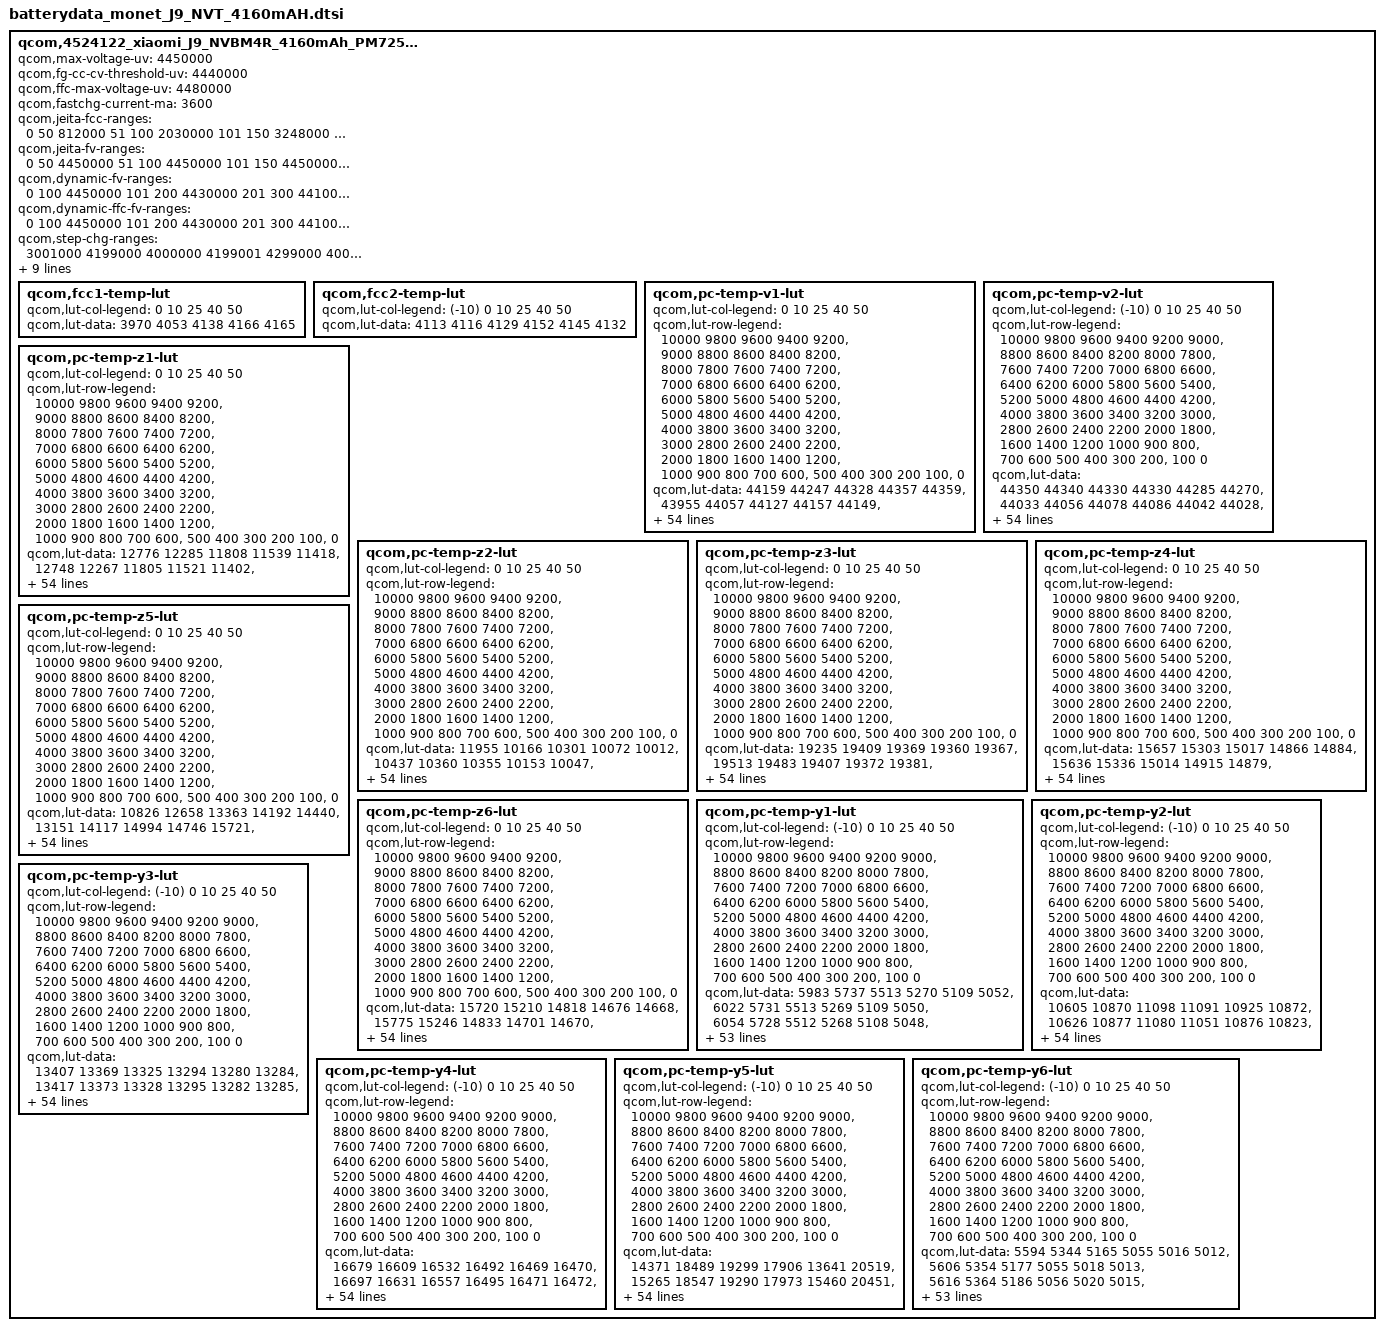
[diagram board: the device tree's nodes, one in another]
qcom,4524122_xiaomi_J9_NVBM4R_4160mAh_PM7250B {
    /* 4524122_xiaomi_J9_NVBM4R_4160mAh_PM7250B_averaged_MasterSlave_Mar27th2020 */
    qcom,max-voltage-uv = <4450000>;
    qcom,fg-cc-cv-threshold-uv = <4440000>;
    qcom,ffc-max-voltage-uv = <4480000>;
    qcom,fastchg-current-ma = <3600>;
    qcom,jeita-fcc-ranges = <0  50  812000
			     51  100  2030000
			     101 150  3248000
			     151 450  3600000
			     451 580  2030000>;
    qcom,jeita-fv-ranges = <0   50  4450000
			    51  100  4450000
			    101 150  4450000
			    151 450  4480000
			    451 580  4100000>;
    qcom,dynamic-fv-ranges = <0    100  4450000
			    101  200  4430000
			    201  300  4410000
			    301  400  4390000
			    401  500  4370000>;
    qcom,dynamic-ffc-fv-ranges = <0    100  4450000
			    101  200  4430000
			    201  300  4410000
			    301  400  4390000
			    401  500  4370000>;
    qcom,step-chg-ranges = <3001000  4199000  4000000
			    4199001  4299000  4000000
			    4299001  4399000  4000000
                            4399001  4450000  4000000
                            4450001  4480000  3248000>;
    qcom,batt-id-kohm = <68>;
    qcom,fg-cc-cv-threshold-mv = <4440>;
    qcom,nom-batt-capacity-mah = <4160>;
    qcom,battery-beta = <4250>;
    qcom,battery-therm-kohm = <100>;
    qcom,cutoff-current-ua = <850000>;
    qcom,battery-type = "J9_NVT_4160mAH";
    qcom,qg-batt-profile-ver = <100>;
    mi,qc3p5-ffc-battery;

	qcom,fcc1-temp-lut {
		qcom,lut-col-legend = <0 10 25 40 50>;
		qcom,lut-data = <3970 4053 4138 4166 4165>;
	};

	qcom,fcc2-temp-lut {
		qcom,lut-col-legend = <(-10) 0 10 25 40 50>;
		qcom,lut-data = <4113 4116 4129 4152 4145 4132>;
	};

	qcom,pc-temp-v1-lut {
		qcom,lut-col-legend = <0 10 25 40 50>;
		qcom,lut-row-legend = <10000 9800 9600 9400 9200>,
			<9000 8800 8600 8400 8200>,
			<8000 7800 7600 7400 7200>,
			<7000 6800 6600 6400 6200>,
			<6000 5800 5600 5400 5200>,
			<5000 4800 4600 4400 4200>,
			<4000 3800 3600 3400 3200>,
			<3000 2800 2600 2400 2200>,
			<2000 1800 1600 1400 1200>,
			<1000 900 800 700 600>,
			<500 400 300 200 100>,
			<0>;
		qcom,lut-data = <44159 44247 44328 44357 44359>,
			<43955 44057 44127 44157 44149>,
			<43742 43859 43926 43951 43947>,
			<43523 43653 43724 43748 43746>,
			<43298 43439 43522 43546 43545>,
			<43069 43215 43309 43338 43338>,
			<42838 42984 43081 43114 43117>,
			<42602 42749 42845 42880 42888>,
			<42369 42511 42608 42644 42656>,
			<42139 42274 42366 42403 42416>,
			<41912 42040 42127 42164 42177>,
			<41698 41809 41891 41928 41941>,
			<41500 41584 41660 41697 41708>,
			<41307 41363 41432 41468 41478>,
			<41103 41149 41209 41243 41252>,
			<40892 40945 40993 41024 41033>,
			<40684 40749 40785 40813 40820>,
			<40481 40557 40585 40609 40615>,
			<40283 40372 40397 40417 40422>,
			<40097 40182 40221 40243 40247>,
			<39929 39961 40026 40057 40060>,
			<39754 39717 39780 39815 39825>,
			<39527 39499 39528 39549 39568>,
			<39265 39308 39327 39337 39356>,
			<39087 39140 39155 39163 39179>,
			<38992 39008 39007 39014 39027>,
			<38918 38901 38880 38886 38898>,
			<38837 38801 38768 38773 38784>,
			<38752 38704 38663 38668 38677>,
			<38671 38614 38566 38569 38575>,
			<38599 38534 38478 38478 38482>,
			<38530 38460 38398 38395 38396>,
			<38471 38395 38325 38317 38317>,
			<38417 38337 38259 38244 38241>,
			<38369 38285 38199 38176 38168>,
			<38327 38236 38143 38108 38094>,
			<38289 38194 38093 38042 38016>,
			<38241 38146 38042 37974 37933>,
			<38160 38071 37969 37888 37837>,
			<38053 37966 37868 37780 37722>,
			<37932 37849 37752 37659 37597>,
			<37787 37713 37622 37527 37465>,
			<37635 37560 37475 37383 37321>,
			<37476 37379 37303 37213 37148>,
			<37334 37226 37163 37091 37028>,
			<37232 37137 37083 37025 36965>,
			<37193 37107 37057 37000 36942>,
			<37163 37088 37036 36985 36923>,
			<37126 37057 37008 36946 36885>,
			<37033 36966 36872 36768 36720>,
			<36715 36631 36487 36386 36352>,
			<36225 36147 35989 35888 35871>,
			<35600 35520 35339 35239 35246>,
			<34746 34657 34443 34341 34391>,
			<33379 33271 32970 32878 33033>,
			<30000 30000 30000 30000 30000>;
	};

	qcom,pc-temp-v2-lut {
		qcom,lut-col-legend = <(-10) 0 10 25 40 50>;
		qcom,lut-row-legend = <10000 9800 9600 9400 9200 9000>,
			<8800 8600 8400 8200 8000 7800>,
			<7600 7400 7200 7000 6800 6600>,
			<6400 6200 6000 5800 5600 5400>,
			<5200 5000 4800 4600 4400 4200>,
			<4000 3800 3600 3400 3200 3000>,
			<2800 2600 2400 2200 2000 1800>,
			<1600 1400 1200 1000 900 800>,
			<700 600 500 400 300 200>,
			<100 0>;
		qcom,lut-data = <44350 44340 44330 44330 44285 44270>,
			<44033 44056 44078 44086 44042 44028>,
			<43743 43792 43840 43853 43809 43797>,
			<43484 43549 43617 43633 43590 43577>,
			<43258 43329 43410 43426 43385 43370>,
			<43034 43109 43200 43214 43175 43160>,
			<42800 42878 42971 42985 42948 42935>,
			<42562 42641 42732 42748 42712 42704>,
			<42323 42402 42493 42510 42475 42470>,
			<42079 42156 42250 42268 42233 42231>,
			<41837 41914 42010 42028 41993 41993>,
			<41593 41679 41773 41789 41757 41758>,
			<41353 41450 41540 41554 41526 41526>,
			<41150 41229 41310 41324 41298 41299>,
			<40994 41016 41085 41101 41076 41076>,
			<40821 40812 40867 40884 40860 40859>,
			<40548 40627 40663 40674 40650 40650>,
			<40200 40450 40466 40469 40447 40446>,
			<39912 40236 40264 40273 40255 40254>,
			<39684 39958 40056 40090 40079 40078>,
			<39474 39672 39838 39892 39889 39891>,
			<39261 39421 39587 39639 39643 39653>,
			<39053 39185 39318 39367 39375 39387>,
			<38863 38981 39098 39148 39159 39170>,
			<38683 38806 38919 38965 38981 38996>,
			<38525 38648 38763 38807 38827 38843>,
			<38401 38500 38626 38673 38694 38707>,
			<38298 38361 38504 38555 38577 38585>,
			<38213 38242 38391 38446 38469 38475>,
			<38143 38135 38285 38347 38368 38375>,
			<38081 38048 38188 38254 38276 38283>,
			<38020 37985 38097 38166 38193 38200>,
			<37962 37937 38013 38084 38117 38123>,
			<37902 37894 37940 38006 38038 38041>,
			<37844 37857 37878 37936 37957 37953>,
			<37784 37820 37820 37862 37870 37856>,
			<37717 37777 37765 37773 37767 37743>,
			<37643 37728 37712 37674 37653 37618>,
			<37560 37664 37646 37579 37548 37506>,
			<37466 37572 37556 37488 37454 37415>,
			<37362 37455 37449 37389 37354 37321>,
			<37246 37317 37325 37272 37234 37201>,
			<37116 37150 37181 37145 37103 37064>,
			<37005 36991 37032 37011 36966 36929>,
			<36909 36854 36906 36915 36876 36830>,
			<36829 36770 36837 36868 36841 36790>,
			<36787 36742 36809 36852 36827 36778>,
			<36739 36697 36775 36830 36805 36756>,
			<36668 36632 36712 36777 36744 36697>,
			<36506 36481 36548 36567 36504 36480>,
			<36191 36167 36164 36138 36066 36057>,
			<35712 35671 35603 35566 35497 35511>,
			<35026 35008 34862 34812 34745 34796>,
			<34045 34080 33824 33752 33703 33819>,
			<32404 32502 32079 32096 32060 32319>,
			<27319 28586 28048 26381 26476 28110>;
	};

	qcom,pc-temp-z1-lut {
		qcom,lut-col-legend = <0 10 25 40 50>;
		qcom,lut-row-legend = <10000 9800 9600 9400 9200>,
			<9000 8800 8600 8400 8200>,
			<8000 7800 7600 7400 7200>,
			<7000 6800 6600 6400 6200>,
			<6000 5800 5600 5400 5200>,
			<5000 4800 4600 4400 4200>,
			<4000 3800 3600 3400 3200>,
			<3000 2800 2600 2400 2200>,
			<2000 1800 1600 1400 1200>,
			<1000 900 800 700 600>,
			<500 400 300 200 100>,
			<0>;
		qcom,lut-data = <12776 12285 11808 11539 11418>,
			<12748 12267 11805 11521 11402>,
			<12735 12255 11799 11508 11395>,
			<12727 12247 11791 11497 11388>,
			<12720 12238 11779 11488 11381>,
			<12711 12226 11767 11480 11376>,
			<12696 12212 11753 11473 11372>,
			<12663 12198 11742 11468 11369>,
			<12636 12182 11736 11464 11367>,
			<12627 12172 11733 11462 11366>,
			<12621 12163 11729 11460 11365>,
			<12614 12153 11725 11457 11363>,
			<12598 12150 11721 11454 11362>,
			<12581 12147 11717 11453 11361>,
			<12574 12144 11714 11452 11360>,
			<12570 12141 11713 11451 11360>,
			<12566 12138 11714 11450 11360>,
			<12549 12137 11716 11450 11361>,
			<12529 12134 11715 11450 11361>,
			<12523 12131 11712 11451 11363>,
			<12523 12130 11710 11453 11364>,
			<12523 12129 11711 11452 11364>,
			<12528 12129 11713 11450 11363>,
			<12542 12128 11715 11450 11363>,
			<12548 12126 11719 11452 11365>,
			<12542 12129 11723 11455 11367>,
			<12533 12140 11725 11458 11370>,
			<12535 12147 11726 11462 11373>,
			<12544 12148 11730 11466 11376>,
			<12551 12147 11738 11469 11379>,
			<12548 12146 11744 11472 11382>,
			<12541 12145 11748 11476 11385>,
			<12538 12145 11751 11480 11388>,
			<12540 12150 11754 11485 11392>,
			<12545 12159 11758 11491 11397>,
			<12554 12166 11762 11497 11402>,
			<12571 12177 11769 11502 11406>,
			<12586 12187 11776 11508 11410>,
			<12592 12193 11782 11513 11415>,
			<12599 12198 11786 11516 11422>,
			<12612 12200 11790 11520 11427>,
			<12639 12204 11796 11524 11429>,
			<12655 12210 11804 11528 11430>,
			<12662 12229 11813 11531 11430>,
			<12661 12227 11823 11535 11433>,
			<12669 12237 11818 11538 11434>,
			<12663 12264 11823 11538 11436>,
			<12661 12407 11821 11542 11437>,
			<12658 12238 11822 11544 11440>,
			<12665 12262 11839 11549 11442>,
			<12696 12256 11838 11553 11448>,
			<12704 12266 11841 11561 11454>,
			<12697 12292 11856 11566 11463>,
			<12720 12299 11873 11581 11474>,
			<12720 12299 11873 11581 11474>,
			<12720 12299 11873 11581 11474>;
	};

	qcom,pc-temp-z2-lut {
		qcom,lut-col-legend = <0 10 25 40 50>;
		qcom,lut-row-legend = <10000 9800 9600 9400 9200>,
			<9000 8800 8600 8400 8200>,
			<8000 7800 7600 7400 7200>,
			<7000 6800 6600 6400 6200>,
			<6000 5800 5600 5400 5200>,
			<5000 4800 4600 4400 4200>,
			<4000 3800 3600 3400 3200>,
			<3000 2800 2600 2400 2200>,
			<2000 1800 1600 1400 1200>,
			<1000 900 800 700 600>,
			<500 400 300 200 100>,
			<0>;
		qcom,lut-data = <11955 10166 10301 10072 10012>,
			<10437 10360 10355 10153 10047>,
			<10314 10378 10382 10150 10027>,
			<10266 10374 10375 10146 10011>,
			<10252 10366 10344 10146 10009>,
			<10241 10348 10314 10143 10012>,
			<10227 10323 10285 10133 9999>,
			<10207 10302 10256 10117 9965>,
			<10192 10282 10233 10100 9946>,
			<10184 10266 10213 10078 9946>,
			<10179 10253 10205 10058 9954>,
			<10189 10243 10207 10034 9947>,
			<10385 10244 10212 10006 9925>,
			<10603 10265 10217 9999 9917>,
			<10571 10287 10228 9987 9922>,
			<10354 10296 10238 9979 9929>,
			<10222 10302 10246 9987 9942>,
			<10228 10308 10252 9999 9959>,
			<10240 10314 10256 10009 9968>,
			<10249 10319 10259 10015 9975>,
			<10257 10326 10265 10024 9986>,
			<10262 10332 10310 10126 10053>,
			<10260 10334 10360 10306 10169>,
			<10254 10319 10361 10375 10246>,
			<10248 10301 10340 10399 10305>,
			<10237 10306 10329 10408 10333>,
			<10227 10336 10330 10336 10248>,
			<10226 10353 10330 10193 10075>,
			<10230 10346 10320 10114 9969>,
			<10235 10336 10277 10072 9897>,
			<10244 10334 10251 10039 9863>,
			<10257 10336 10246 10005 9867>,
			<10269 10339 10243 9977 9878>,
			<10279 10346 10251 9977 9893>,
			<10289 10356 10293 10017 9928>,
			<10296 10364 10331 10062 9972>,
			<10303 10369 10351 10097 10024>,
			<10312 10376 10369 10134 10081>,
			<10333 10391 10396 10173 10123>,
			<10356 10412 10435 10226 10158>,
			<10362 10421 10455 10271 10175>,
			<10360 10423 10456 10305 10163>,
			<10336 10425 10457 10324 10145>,
			<10208 10440 10454 10308 10146>,
			<10607 10573 10475 10239 10128>,
			<10770 10624 10465 10177 10081>,
			<10868 10605 10439 10188 10089>,
			<11496 10612 10455 10214 10109>,
			<12103 10624 10450 10272 10182>,
			<11607 10753 10526 10229 10165>,
			<10857 10809 10419 10062 9989>,
			<10957 10849 10365 10021 9931>,
			<10457 10891 10314 9977 9891>,
			<10210 10754 10267 9925 9829>,
			<10210 10754 10267 9925 9829>,
			<10210 10754 10267 9925 9829>;
	};

	qcom,pc-temp-z3-lut {
		qcom,lut-col-legend = <0 10 25 40 50>;
		qcom,lut-row-legend = <10000 9800 9600 9400 9200>,
			<9000 8800 8600 8400 8200>,
			<8000 7800 7600 7400 7200>,
			<7000 6800 6600 6400 6200>,
			<6000 5800 5600 5400 5200>,
			<5000 4800 4600 4400 4200>,
			<4000 3800 3600 3400 3200>,
			<3000 2800 2600 2400 2200>,
			<2000 1800 1600 1400 1200>,
			<1000 900 800 700 600>,
			<500 400 300 200 100>,
			<0>;
		qcom,lut-data = <19235 19409 19369 19360 19367>,
			<19513 19483 19407 19372 19381>,
			<19652 19528 19435 19394 19391>,
			<19713 19562 19450 19409 19400>,
			<19737 19580 19459 19419 19412>,
			<19751 19590 19466 19428 19421>,
			<19759 19595 19473 19437 19426>,
			<19766 19596 19477 19445 19430>,
			<19769 19595 19477 19447 19430>,
			<19766 19593 19476 19444 19428>,
			<19760 19591 19473 19440 19426>,
			<19758 19587 19465 19434 19423>,
			<19768 19583 19455 19427 19420>,
			<19779 19575 19451 19422 19417>,
			<19772 19569 19449 19419 19415>,
			<19740 19565 19447 19416 19412>,
			<19721 19562 19444 19413 19409>,
			<19721 19558 19441 19410 19405>,
			<19721 19551 19438 19406 19400>,
			<19721 19546 19434 19396 19391>,
			<19715 19556 19433 19389 19386>,
			<19710 19583 19443 19396 19389>,
			<19719 19594 19457 19412 19396>,
			<19743 19573 19454 19426 19408>,
			<19752 19548 19440 19441 19430>,
			<19739 19549 19432 19451 19445>,
			<19722 19563 19452 19454 19446>,
			<19718 19574 19477 19456 19445>,
			<19719 19579 19480 19455 19444>,
			<19720 19582 19478 19446 19436>,
			<19717 19582 19475 19435 19426>,
			<19713 19576 19468 19426 19418>,
			<19708 19570 19461 19417 19408>,
			<19704 19565 19455 19408 19398>,
			<19699 19560 19451 19401 19386>,
			<19695 19557 19446 19394 19378>,
			<19692 19555 19440 19388 19375>,
			<19687 19552 19434 19383 19373>,
			<19681 19548 19431 19382 19372>,
			<19673 19541 19429 19385 19373>,
			<19666 19534 19428 19389 19374>,
			<19660 19530 19428 19394 19379>,
			<19620 19523 19427 19399 19385>,
			<19447 19513 19423 19401 19389>,
			<19288 19479 19410 19394 19387>,
			<19260 19456 19389 19372 19373>,
			<19259 19459 19385 19370 19364>,
			<19258 19446 19387 19355 19353>,
			<19258 19438 19371 19349 19344>,
			<19258 19393 19375 19368 19351>,
			<19259 19384 19409 19387 19372>,
			<19259 19351 19409 19387 19372>,
			<19261 19337 19412 19391 19376>,
			<19261 19322 19390 19388 19376>,
			<19261 19322 19390 19388 19376>,
			<19261 19322 19390 19388 19376>;
	};

	qcom,pc-temp-z4-lut {
		qcom,lut-col-legend = <0 10 25 40 50>;
		qcom,lut-row-legend = <10000 9800 9600 9400 9200>,
			<9000 8800 8600 8400 8200>,
			<8000 7800 7600 7400 7200>,
			<7000 6800 6600 6400 6200>,
			<6000 5800 5600 5400 5200>,
			<5000 4800 4600 4400 4200>,
			<4000 3800 3600 3400 3200>,
			<3000 2800 2600 2400 2200>,
			<2000 1800 1600 1400 1200>,
			<1000 900 800 700 600>,
			<500 400 300 200 100>,
			<0>;
		qcom,lut-data = <15657 15303 15017 14866 14884>,
			<15636 15336 15014 14915 14879>,
			<15578 15317 15007 14899 14871>,
			<15507 15240 14987 14881 14859>,
			<15411 15162 14942 14854 14838>,
			<15302 15094 14900 14827 14815>,
			<15214 15030 14869 14804 14796>,
			<15140 14979 14840 14782 14778>,
			<15078 14935 14814 14765 14764>,
			<15031 14899 14789 14751 14751>,
			<14992 14869 14775 14741 14743>,
			<14945 14844 14769 14738 14739>,
			<14872 14827 14765 14736 14736>,
			<14814 14813 14758 14733 14733>,
			<14812 14804 14751 14728 14729>,
			<14834 14798 14744 14722 14724>,
			<14851 14795 14739 14717 14721>,
			<14859 14794 14734 14712 14717>,
			<14865 14798 14731 14708 14713>,
			<14868 14805 14728 14704 14706>,
			<14870 14816 14728 14702 14701>,
			<14874 14836 14760 14730 14730>,
			<14898 14860 14808 14782 14783>,
			<14952 14906 14839 14794 14794>,
			<14976 14946 14864 14786 14779>,
			<14964 14942 14873 14774 14761>,
			<14942 14905 14842 14758 14744>,
			<14923 14872 14796 14739 14729>,
			<14903 14851 14776 14730 14722>,
			<14888 14835 14766 14727 14718>,
			<14881 14828 14759 14724 14715>,
			<14875 14825 14755 14721 14711>,
			<14872 14823 14752 14718 14707>,
			<14871 14821 14752 14716 14704>,
			<14870 14820 14752 14715 14700>,
			<14866 14818 14752 14714 14699>,
			<14857 14814 14752 14714 14699>,
			<14848 14809 14752 14715 14700>,
			<14840 14805 14753 14718 14703>,
			<14832 14802 14756 14726 14716>,
			<14818 14795 14757 14732 14725>,
			<14795 14777 14746 14723 14719>,
			<14806 14757 14730 14713 14712>,
			<14937 14741 14723 14714 14719>,
			<14988 14705 14700 14699 14704>,
			<14985 14687 14684 14679 14670>,
			<14982 14676 14673 14669 14664>,
			<14979 14675 14657 14660 14653>,
			<14972 14677 14659 14645 14640>,
			<14970 14728 14663 14654 14657>,
			<14974 14751 14654 14672 14685>,
			<14979 14790 14657 14676 14693>,
			<14981 14807 14659 14678 14696>,
			<14987 14828 14684 14682 14696>,
			<14987 14828 14684 14682 14696>,
			<14987 14828 14684 14682 14696>;
	};

	qcom,pc-temp-z5-lut {
		qcom,lut-col-legend = <0 10 25 40 50>;
		qcom,lut-row-legend = <10000 9800 9600 9400 9200>,
			<9000 8800 8600 8400 8200>,
			<8000 7800 7600 7400 7200>,
			<7000 6800 6600 6400 6200>,
			<6000 5800 5600 5400 5200>,
			<5000 4800 4600 4400 4200>,
			<4000 3800 3600 3400 3200>,
			<3000 2800 2600 2400 2200>,
			<2000 1800 1600 1400 1200>,
			<1000 900 800 700 600>,
			<500 400 300 200 100>,
			<0>;
		qcom,lut-data = <10826 12658 13363 14192 14440>,
			<13151 14117 14994 14746 15721>,
			<14731 15294 16156 16102 16816>,
			<15841 16312 16689 17096 17867>,
			<16587 17095 17008 17798 18978>,
			<17189 17638 17337 18521 20037>,
			<17892 18101 17759 19513 20921>,
			<18736 18635 18193 20616 21689>,
			<19586 19235 18708 21510 22424>,
			<20306 19887 19435 22370 23412>,
			<20975 20609 19739 22846 24208>,
			<21794 21372 19585 22545 24441>,
			<23192 22126 19391 21961 24629>,
			<24515 22928 19505 21862 24944>,
			<24913 23602 20075 22306 25689>,
			<25029 24107 20664 22918 26583>,
			<25301 24517 21227 23765 27555>,
			<26899 24594 21746 24714 28517>,
			<29010 24185 22042 24792 28708>,
			<29262 23795 22287 23767 28325>,
			<27591 26221 22659 22985 28009>,
			<26182 32921 24248 24760 28446>,
			<27816 35654 26002 28017 29100>,
			<31924 29512 24836 28287 28772>,
			<33582 22309 19790 24727 26226>,
			<30712 21611 17179 22072 24446>,
			<27183 22526 18637 22861 25218>,
			<26886 23784 21032 24376 26656>,
			<28345 25878 22748 24934 27241>,
			<30007 28398 24201 24934 27489>,
			<31482 30095 25379 24875 27597>,
			<32937 31442 26252 24722 27340>,
			<33578 32295 27039 24451 26689>,
			<33830 32682 28092 24450 25841>,
			<33980 32980 29467 24612 24439>,
			<33970 33136 30103 24692 23612>,
			<33762 33193 29552 24519 24327>,
			<33675 33155 28555 24262 25556>,
			<33937 32651 27678 24221 25607>,
			<34324 31576 26731 24354 24259>,
			<34551 31008 26290 24601 23324>,
			<34704 30865 26690 25834 24134>,
			<32980 30666 27039 27284 25806>,
			<23023 29830 25836 28272 28351>,
			<13447 30987 25646 27577 29364>,
			<11556 28634 22750 21485 24692>,
			<11514 30354 23189 22314 21675>,
			<11450 25273 26467 20884 21410>,
			<11439 23686 22044 24258 25222>,
			<11466 18222 20892 31225 27493>,
			<11489 16267 28390 24799 21710>,
			<11438 13371 26522 22077 19177>,
			<11390 12815 25630 20547 17688>,
			<11324 12336 17751 17683 15761>,
			<11324 12336 17751 17683 15761>,
			<11324 12336 17751 17683 15761>;
	};

	qcom,pc-temp-z6-lut {
		qcom,lut-col-legend = <0 10 25 40 50>;
		qcom,lut-row-legend = <10000 9800 9600 9400 9200>,
			<9000 8800 8600 8400 8200>,
			<8000 7800 7600 7400 7200>,
			<7000 6800 6600 6400 6200>,
			<6000 5800 5600 5400 5200>,
			<5000 4800 4600 4400 4200>,
			<4000 3800 3600 3400 3200>,
			<3000 2800 2600 2400 2200>,
			<2000 1800 1600 1400 1200>,
			<1000 900 800 700 600>,
			<500 400 300 200 100>,
			<0>;
		qcom,lut-data = <15720 15210 14818 14676 14668>,
			<15775 15246 14833 14701 14670>,
			<15771 15241 14839 14702 14670>,
			<15758 15210 14834 14701 14669>,
			<15699 15174 14815 14695 14665>,
			<15609 15135 14798 14687 14660>,
			<15541 15094 14784 14681 14655>,
			<15486 15060 14771 14675 14650>,
			<15436 15029 14759 14668 14644>,
			<15391 15002 14746 14660 14638>,
			<15350 14979 14735 14653 14632>,
			<15313 14960 14727 14647 14628>,
			<15276 14946 14719 14642 14625>,
			<15246 14934 14713 14638 14622>,
			<15226 14925 14709 14633 14618>,
			<15210 14918 14704 14629 14615>,
			<15202 14913 14700 14625 14611>,
			<15201 14911 14696 14621 14608>,
			<15201 14909 14693 14616 14603>,
			<15200 14908 14689 14609 14595>,
			<15199 14915 14689 14605 14590>,
			<15198 14938 14709 14621 14603>,
			<15212 14955 14736 14652 14629>,
			<15247 14965 14746 14664 14641>,
			<15263 14972 14752 14668 14646>,
			<15252 14970 14753 14670 14648>,
			<15235 14963 14750 14667 14645>,
			<15226 14956 14745 14661 14638>,
			<15220 14952 14740 14655 14633>,
			<15216 14948 14736 14650 14628>,
			<15212 14945 14732 14644 14623>,
			<15209 14942 14727 14639 14617>,
			<15208 14940 14723 14633 14610>,
			<15208 14939 14721 14629 14604>,
			<15208 14938 14720 14625 14596>,
			<15208 14937 14719 14621 14591>,
			<15208 14938 14717 14619 14590>,
			<15208 14939 14716 14617 14589>,
			<15212 14940 14716 14617 14590>,
			<15217 14941 14718 14623 14596>,
			<15218 14941 14720 14627 14601>,
			<15219 14937 14716 14627 14601>,
			<15217 14933 14711 14626 14601>,
			<15208 14930 14708 14628 14607>,
			<15170 14909 14695 14619 14600>,
			<15160 14894 14679 14599 14578>,
			<15159 14890 14672 14594 14572>,
			<15159 14886 14667 14582 14561>,
			<15160 14886 14661 14573 14550>,
			<15169 14893 14668 14587 14561>,
			<15180 14904 14684 14607 14587>,
			<15191 14910 14689 14611 14594>,
			<15203 14917 14694 14617 14600>,
			<15222 14929 14698 14621 14604>,
			<15222 14929 14698 14621 14604>,
			<15222 14929 14698 14621 14604>;
	};

	qcom,pc-temp-y1-lut {
		qcom,lut-col-legend = <(-10) 0 10 25 40 50>;
		qcom,lut-row-legend = <10000 9800 9600 9400 9200 9000>,
			<8800 8600 8400 8200 8000 7800>,
			<7600 7400 7200 7000 6800 6600>,
			<6400 6200 6000 5800 5600 5400>,
			<5200 5000 4800 4600 4400 4200>,
			<4000 3800 3600 3400 3200 3000>,
			<2800 2600 2400 2200 2000 1800>,
			<1600 1400 1200 1000 900 800>,
			<700 600 500 400 300 200>,
			<100 0>;
		qcom,lut-data = <5983 5737 5513 5270 5109 5052>,
			<6022 5731 5513 5269 5109 5050>,
			<6054 5728 5512 5268 5108 5048>,
			<6076 5727 5511 5266 5107 5047>,
			<6090 5728 5511 5263 5106 5045>,
			<6095 5730 5511 5261 5104 5044>,
			<6087 5735 5510 5259 5102 5043>,
			<6072 5743 5510 5257 5100 5042>,
			<6068 5746 5509 5255 5099 5042>,
			<6075 5743 5505 5252 5099 5042>,
			<6082 5741 5501 5250 5098 5042>,
			<6082 5738 5499 5249 5098 5042>,
			<6082 5734 5498 5248 5099 5041>,
			<6082 5735 5498 5248 5098 5041>,
			<6081 5744 5498 5247 5096 5040>,
			<6081 5752 5497 5247 5094 5040>,
			<6089 5750 5496 5248 5094 5040>,
			<6104 5745 5495 5249 5095 5040>,
			<6113 5742 5494 5249 5095 5041>,
			<6117 5743 5494 5250 5095 5041>,
			<6119 5746 5494 5251 5095 5041>,
			<6115 5751 5496 5252 5097 5042>,
			<6107 5757 5498 5254 5099 5043>,
			<6115 5759 5499 5256 5101 5045>,
			<6275 5753 5498 5260 5103 5046>,
			<6434 5748 5497 5263 5104 5048>,
			<6369 5748 5498 5266 5106 5050>,
			<6165 5751 5502 5268 5108 5051>,
			<6081 5752 5504 5270 5110 5053>,
			<6082 5747 5505 5272 5111 5054>,
			<6085 5742 5506 5274 5113 5056>,
			<6085 5740 5506 5274 5114 5058>,
			<6083 5738 5504 5275 5116 5061>,
			<6079 5737 5504 5276 5118 5062>,
			<6070 5739 5504 5276 5120 5063>,
			<6061 5741 5506 5277 5121 5064>,
			<6061 5739 5507 5278 5123 5065>,
			<6069 5730 5508 5280 5124 5066>,
			<6073 5724 5509 5281 5124 5066>,
			<6066 5722 5510 5281 5125 5067>,
			<6056 5722 5510 5281 5126 5068>,
			<6053 5725 5511 5283 5127 5070>,
			<6056 5733 5514 5286 5128 5072>,
			<6055 5738 5518 5290 5130 5074>,
			<6053 5741 5519 5296 5134 5076>,
			<6097 5745 5534 5296 5136 5076>,
			<6126 5759 5539 5301 5135 5079>,
			<6201 5773 5539 5298 5138 5080>,
			<6179 5770 5536 5301 5139 5081>,
			<6132 5774 5532 5313 5139 5082>,
			<6151 5778 5535 5311 5140 5083>,
			<6191 5783 5545 5315 5145 5088>,
			<6254 5820 5548 5322 5150 5094>,
			<6329 5853 5565 5336 5161 5105>,
			<6329 5853 5565 5336 5161 5105>,
			<6329 5853 5565 5336 5161 5105>;
	};

	qcom,pc-temp-y2-lut {
		qcom,lut-col-legend = <(-10) 0 10 25 40 50>;
		qcom,lut-row-legend = <10000 9800 9600 9400 9200 9000>,
			<8800 8600 8400 8200 8000 7800>,
			<7600 7400 7200 7000 6800 6600>,
			<6400 6200 6000 5800 5600 5400>,
			<5200 5000 4800 4600 4400 4200>,
			<4000 3800 3600 3400 3200 3000>,
			<2800 2600 2400 2200 2000 1800>,
			<1600 1400 1200 1000 900 800>,
			<700 600 500 400 300 200>,
			<100 0>;
		qcom,lut-data = <10605 10870 11098 11091 10925 10872>,
			<10626 10877 11080 11051 10876 10823>,
			<10654 10880 11061 11008 10825 10775>,
			<10682 10881 11040 10965 10776 10731>,
			<10705 10880 11020 10929 10733 10690>,
			<10714 10878 11000 10905 10700 10654>,
			<10711 10872 10979 10892 10676 10621>,
			<10706 10859 10957 10882 10656 10591>,
			<10704 10847 10936 10877 10641 10573>,
			<10700 10832 10910 10875 10626 10560>,
			<10697 10823 10894 10875 10615 10552>,
			<10717 10823 10896 10866 10606 10551>,
			<10761 10824 10899 10852 10598 10553>,
			<10802 10834 10905 10851 10593 10549>,
			<10848 10917 10922 10860 10589 10534>,
			<10883 10990 10948 10874 10586 10525>,
			<10896 10997 10993 10899 10598 10525>,
			<10904 10998 11058 10943 10627 10528>,
			<10911 11005 11109 11005 10674 10537>,
			<10919 11038 11155 11109 10781 10582>,
			<10925 11065 11180 11170 10872 10642>,
			<10922 11062 11172 11146 10913 10714>,
			<10914 11053 11155 11105 10941 10792>,
			<10904 11050 11150 11095 10940 10814>,
			<10883 11059 11157 11094 10901 10809>,
			<10856 11067 11166 11094 10873 10806>,
			<10738 11063 11174 11109 10885 10813>,
			<10458 11050 11184 11138 10913 10827>,
			<10325 11045 11196 11163 10936 10844>,
			<10111 11057 11212 11195 10956 10888>,
			<9855 11070 11225 11221 10978 10936>,
			<9784 11058 11227 11232 11008 10969>,
			<9754 11010 11226 11242 11043 10997>,
			<9734 10961 11224 11253 11071 11023>,
			<9719 10922 11216 11268 11104 11055>,
			<9708 10880 11202 11278 11123 11076>,
			<9698 10832 11179 11245 11094 11052>,
			<9690 10775 11142 11187 11036 10992>,
			<9684 10696 11103 11166 11008 10953>,
			<9680 10476 11058 11160 10986 10927>,
			<9678 10224 11004 11154 10965 10901>,
			<9675 10058 10936 11132 10946 10874>,
			<9673 9782 10855 11097 10919 10842>,
			<9671 9708 10770 11049 10841 10773>,
			<9669 9690 10656 10997 10763 10648>,
			<9666 9678 10576 10942 10689 10589>,
			<9664 9674 10560 10943 10706 10624>,
			<9663 9671 10526 10949 10751 10611>,
			<9661 9668 10506 10987 10753 10621>,
			<9658 9666 10365 10974 10714 10616>,
			<9655 9663 10174 10926 10654 10561>,
			<9650 9660 10041 10850 10589 10518>,
			<9648 9657 9775 10762 10514 10431>,
			<9648 9652 9702 10686 10358 10278>,
			<9648 9652 9702 10686 10358 10278>,
			<9648 9652 9702 10686 10358 10278>;
	};

	qcom,pc-temp-y3-lut {
		qcom,lut-col-legend = <(-10) 0 10 25 40 50>;
		qcom,lut-row-legend = <10000 9800 9600 9400 9200 9000>,
			<8800 8600 8400 8200 8000 7800>,
			<7600 7400 7200 7000 6800 6600>,
			<6400 6200 6000 5800 5600 5400>,
			<5200 5000 4800 4600 4400 4200>,
			<4000 3800 3600 3400 3200 3000>,
			<2800 2600 2400 2200 2000 1800>,
			<1600 1400 1200 1000 900 800>,
			<700 600 500 400 300 200>,
			<100 0>;
		qcom,lut-data = <13407 13369 13325 13294 13280 13284>,
			<13417 13373 13328 13295 13282 13285>,
			<13427 13377 13331 13296 13285 13286>,
			<13437 13381 13334 13297 13288 13287>,
			<13445 13385 13336 13298 13290 13288>,
			<13451 13388 13338 13299 13292 13289>,
			<13455 13391 13339 13299 13293 13290>,
			<13458 13393 13340 13300 13293 13291>,
			<13458 13395 13341 13301 13293 13292>,
			<13454 13397 13342 13303 13293 13293>,
			<13450 13399 13343 13304 13293 13293>,
			<13450 13401 13344 13304 13294 13294>,
			<13450 13403 13346 13303 13295 13295>,
			<13449 13402 13346 13304 13296 13296>,
			<13442 13389 13345 13308 13299 13296>,
			<13436 13378 13344 13311 13300 13297>,
			<13433 13379 13340 13312 13301 13297>,
			<13431 13383 13334 13312 13301 13297>,
			<13428 13384 13332 13311 13302 13298>,
			<13420 13378 13335 13310 13303 13299>,
			<13411 13371 13337 13308 13304 13300>,
			<13404 13365 13334 13305 13300 13297>,
			<13396 13359 13327 13301 13293 13289>,
			<13388 13354 13323 13298 13290 13287>,
			<13376 13351 13321 13295 13288 13287>,
			<13366 13348 13319 13293 13288 13287>,
			<13360 13345 13318 13293 13287 13286>,
			<13354 13342 13318 13293 13288 13285>,
			<13352 13338 13317 13293 13287 13285>,
			<13355 13330 13316 13294 13286 13286>,
			<13361 13323 13315 13294 13285 13287>,
			<13368 13323 13314 13294 13285 13287>,
			<13378 13327 13314 13293 13285 13287>,
			<13390 13331 13314 13293 13285 13287>,
			<13404 13337 13314 13293 13287 13288>,
			<13420 13344 13314 13293 13288 13288>,
			<13436 13349 13315 13292 13288 13287>,
			<13452 13353 13316 13291 13287 13286>,
			<13470 13359 13317 13291 13287 13285>,
			<13495 13367 13317 13292 13288 13286>,
			<13524 13378 13318 13293 13289 13287>,
			<13553 13391 13320 13293 13289 13287>,
			<13583 13408 13324 13293 13288 13285>,
			<13626 13433 13327 13294 13287 13285>,
			<13689 13473 13331 13297 13289 13286>,
			<13785 13532 13336 13300 13295 13291>,
			<13833 13555 13338 13304 13296 13292>,
			<13909 13598 13346 13308 13298 13294>,
			<14027 13663 13357 13310 13297 13293>,
			<14206 13736 13364 13306 13293 13291>,
			<14594 13833 13371 13305 13293 13291>,
			<16043 14005 13394 13307 13296 13294>,
			<19463 14392 13449 13313 13301 13300>,
			<29352 15767 13587 13326 13310 13309>,
			<29352 15767 13587 13326 13310 13309>,
			<29352 15767 13587 13326 13310 13309>;
	};

	qcom,pc-temp-y4-lut {
		qcom,lut-col-legend = <(-10) 0 10 25 40 50>;
		qcom,lut-row-legend = <10000 9800 9600 9400 9200 9000>,
			<8800 8600 8400 8200 8000 7800>,
			<7600 7400 7200 7000 6800 6600>,
			<6400 6200 6000 5800 5600 5400>,
			<5200 5000 4800 4600 4400 4200>,
			<4000 3800 3600 3400 3200 3000>,
			<2800 2600 2400 2200 2000 1800>,
			<1600 1400 1200 1000 900 800>,
			<700 600 500 400 300 200>,
			<100 0>;
		qcom,lut-data = <16679 16609 16532 16492 16469 16470>,
			<16697 16631 16557 16495 16471 16472>,
			<16738 16674 16584 16497 16473 16475>,
			<16786 16725 16609 16498 16474 16477>,
			<16826 16767 16628 16500 16475 16479>,
			<16844 16787 16636 16500 16476 16479>,
			<16844 16787 16632 16500 16475 16479>,
			<16843 16786 16625 16500 16474 16478>,
			<16843 16783 16621 16500 16474 16477>,
			<16852 16774 16617 16501 16476 16476>,
			<16862 16768 16616 16503 16478 16476>,
			<16869 16770 16617 16508 16480 16476>,
			<16877 16775 16621 16515 16483 16477>,
			<16898 16790 16627 16520 16485 16478>,
			<16987 16852 16639 16522 16487 16480>,
			<17058 16911 16657 16526 16490 16484>,
			<17001 16932 16697 16535 16495 16488>,
			<16861 16949 16750 16552 16504 16493>,
			<16788 16948 16763 16575 16518 16502>,
			<16763 16877 16752 16614 16544 16524>,
			<16741 16788 16736 16637 16560 16539>,
			<16711 16729 16692 16607 16546 16530>,
			<16678 16679 16618 16551 16515 16507>,
			<16653 16644 16576 16520 16496 16491>,
			<16631 16621 16556 16501 16483 16479>,
			<16617 16601 16543 16493 16476 16473>,
			<16623 16576 16539 16493 16477 16473>,
			<16642 16550 16536 16495 16478 16474>,
			<16658 16537 16534 16497 16481 16475>,
			<16672 16534 16532 16503 16489 16478>,
			<16684 16536 16530 16509 16498 16484>,
			<16692 16540 16525 16515 16508 16493>,
			<16698 16548 16518 16520 16519 16506>,
			<16703 16557 16516 16524 16523 16514>,
			<16708 16570 16518 16526 16525 16518>,
			<16713 16586 16520 16527 16525 16521>,
			<16721 16606 16527 16516 16517 16515>,
			<16731 16631 16540 16495 16500 16501>,
			<16735 16648 16550 16488 16495 16497>,
			<16733 16660 16555 16485 16497 16508>,
			<16728 16668 16560 16484 16499 16519>,
			<16720 16670 16566 16486 16496 16516>,
			<16704 16667 16572 16489 16488 16502>,
			<16702 16659 16574 16482 16465 16473>,
			<16706 16650 16577 16482 16459 16460>,
			<16729 16656 16583 16494 16502 16521>,
			<16728 16654 16581 16516 16538 16556>,
			<16750 16679 16603 16551 16574 16591>,
			<16771 16708 16638 16581 16588 16603>,
			<16781 16741 16668 16543 16522 16546>,
			<16767 16758 16656 16505 16485 16490>,
			<16886 16774 16666 16509 16485 16488>,
			<17419 16835 16724 16527 16486 16486>,
			<19987 17285 16838 16582 16525 16514>,
			<19987 17285 16838 16582 16525 16514>,
			<19987 17285 16838 16582 16525 16514>;
	};

	qcom,pc-temp-y5-lut {
		qcom,lut-col-legend = <(-10) 0 10 25 40 50>;
		qcom,lut-row-legend = <10000 9800 9600 9400 9200 9000>,
			<8800 8600 8400 8200 8000 7800>,
			<7600 7400 7200 7000 6800 6600>,
			<6400 6200 6000 5800 5600 5400>,
			<5200 5000 4800 4600 4400 4200>,
			<4000 3800 3600 3400 3200 3000>,
			<2800 2600 2400 2200 2000 1800>,
			<1600 1400 1200 1000 900 800>,
			<700 600 500 400 300 200>,
			<100 0>;
		qcom,lut-data = <14371 18489 19299 17906 13641 20519>,
			<15265 18547 19290 17973 15460 20451>,
			<16231 18647 19230 17804 17040 20313>,
			<17164 18768 19131 17508 18299 20159>,
			<17956 18891 19007 17196 19156 20046>,
			<18501 18995 18873 16975 19530 20029>,
			<18857 19180 18700 16746 19329 20106>,
			<19108 19416 18507 16467 18838 20186>,
			<19050 19436 18355 16326 18351 20177>,
			<18240 19183 18069 16220 17211 19959>,
			<17397 18922 17737 16063 16374 19662>,
			<16945 18739 17383 15486 16166 19326>,
			<16606 18470 16930 14739 16034 18898>,
			<16653 17996 16375 14662 16041 18452>,
			<17850 16451 15589 15073 16246 17958>,
			<19291 15253 15046 15353 16313 17427>,
			<20550 16735 14932 15039 15821 16768>,
			<22005 20148 14953 14505 15138 16060>,
			<22579 21755 15433 14437 14997 15652>,
			<22478 22294 18265 14837 15099 15390>,
			<22194 22630 20956 15487 15291 15263>,
			<21835 22853 21770 17258 16515 15798>,
			<21218 23090 22271 19519 18472 17120>,
			<20318 23287 22451 19886 19034 18330>,
			<18416 23555 22417 19252 19121 19670>,
			<16319 23774 22392 18737 19156 20528>,
			<14823 23704 22629 18607 18874 19604>,
			<13442 23268 23039 18520 18188 17516>,
			<12866 22498 23222 18575 17466 16762>,
			<12749 19107 23204 19031 16382 16731>,
			<12690 15761 23209 19379 15708 16731>,
			<12712 15557 23660 19281 15778 16710>,
			<12819 15866 24475 19072 16018 16695>,
			<12966 16305 24667 19229 16496 16873>,
			<13271 17293 23895 20426 17969 18293>,
			<13594 18367 22831 21287 19560 19757>,
			<13700 18845 21900 21165 20632 20255>,
			<13744 19157 20852 20901 21585 20587>,
			<13795 19291 19858 20768 22434 20976>,
			<13947 18694 18783 20688 23209 21583>,
			<14114 17798 18020 20546 23992 22336>,
			<14035 16909 17914 20056 25047 23679>,
			<13589 14972 17893 19560 25839 25430>,
			<13295 14481 18039 19427 22763 24501>,
			<13107 14364 18023 19122 19681 20451>,
			<13028 14221 17490 18145 17667 15403>,
			<13044 14263 17249 18452 16442 14792>,
			<13167 13812 17281 18350 15930 14471>,
			<13678 14284 17817 18499 15570 14263>,
			<13741 14548 18019 18729 16143 14750>,
			<13559 14443 17358 20423 17311 16276>,
			<12241 14217 16652 20085 17138 15806>,
			<10478 13965 15103 20397 18017 16706>,
			<9427 11915 14307 23070 24173 22224>,
			<9427 11915 14307 23070 24173 22224>,
			<9427 11915 14307 23070 24173 22224>;
	};

	qcom,pc-temp-y6-lut {
		qcom,lut-col-legend = <(-10) 0 10 25 40 50>;
		qcom,lut-row-legend = <10000 9800 9600 9400 9200 9000>,
			<8800 8600 8400 8200 8000 7800>,
			<7600 7400 7200 7000 6800 6600>,
			<6400 6200 6000 5800 5600 5400>,
			<5200 5000 4800 4600 4400 4200>,
			<4000 3800 3600 3400 3200 3000>,
			<2800 2600 2400 2200 2000 1800>,
			<1600 1400 1200 1000 900 800>,
			<700 600 500 400 300 200>,
			<100 0>;
		qcom,lut-data = <5594 5344 5165 5055 5016 5012>,
			<5606 5354 5177 5055 5018 5013>,
			<5616 5364 5186 5056 5020 5015>,
			<5624 5374 5191 5057 5022 5016>,
			<5629 5381 5194 5057 5024 5017>,
			<5630 5384 5195 5058 5025 5018>,
			<5629 5383 5193 5058 5025 5019>,
			<5625 5380 5188 5058 5025 5019>,
			<5621 5377 5185 5058 5026 5020>,
			<5617 5373 5183 5059 5026 5020>,
			<5614 5370 5182 5060 5026 5021>,
			<5615 5370 5182 5062 5027 5021>,
			<5616 5371 5182 5063 5029 5022>,
			<5620 5372 5183 5065 5031 5023>,
			<5642 5379 5184 5068 5032 5024>,
			<5660 5387 5187 5071 5035 5025>,
			<5647 5396 5195 5075 5037 5027>,
			<5613 5405 5206 5079 5039 5028>,
			<5593 5406 5208 5085 5043 5031>,
			<5583 5384 5207 5095 5052 5038>,
			<5575 5355 5204 5100 5057 5043>,
			<5565 5336 5190 5090 5050 5038>,
			<5556 5319 5164 5071 5036 5026>,
			<5548 5309 5150 5060 5028 5019>,
			<5541 5302 5143 5053 5023 5016>,
			<5536 5298 5140 5049 5021 5014>,
			<5537 5292 5139 5050 5021 5014>,
			<5543 5287 5139 5051 5022 5013>,
			<5550 5285 5139 5052 5023 5014>,
			<5561 5284 5139 5054 5024 5015>,
			<5575 5285 5139 5057 5026 5018>,
			<5589 5290 5139 5058 5029 5021>,
			<5606 5302 5139 5060 5032 5024>,
			<5624 5317 5139 5061 5034 5027>,
			<5643 5334 5141 5063 5036 5029>,
			<5665 5355 5144 5064 5037 5030>,
			<5688 5378 5149 5060 5034 5028>,
			<5713 5404 5156 5053 5029 5023>,
			<5740 5430 5163 5052 5027 5021>,
			<5767 5455 5170 5052 5029 5025>,
			<5796 5481 5178 5053 5031 5029>,
			<5826 5508 5189 5054 5030 5028>,
			<5857 5537 5204 5056 5027 5023>,
			<5901 5574 5222 5056 5021 5015>,
			<5966 5625 5246 5059 5020 5013>,
			<6072 5699 5268 5066 5038 5034>,
			<6135 5737 5272 5076 5049 5046>,
			<6219 5791 5298 5088 5061 5057>,
			<6339 5863 5330 5099 5064 5060>,
			<6514 5945 5358 5084 5042 5042>,
			<6882 6048 5378 5074 5033 5027>,
			<8177 6215 5434 5079 5035 5029>,
			<10966 6584 5539 5091 5040 5034>,
			<18706 7898 5736 5121 5061 5051>,
			<18706 7898 5736 5121 5061 5051>,
			<18706 7898 5736 5121 5061 5051>;
	};

};
